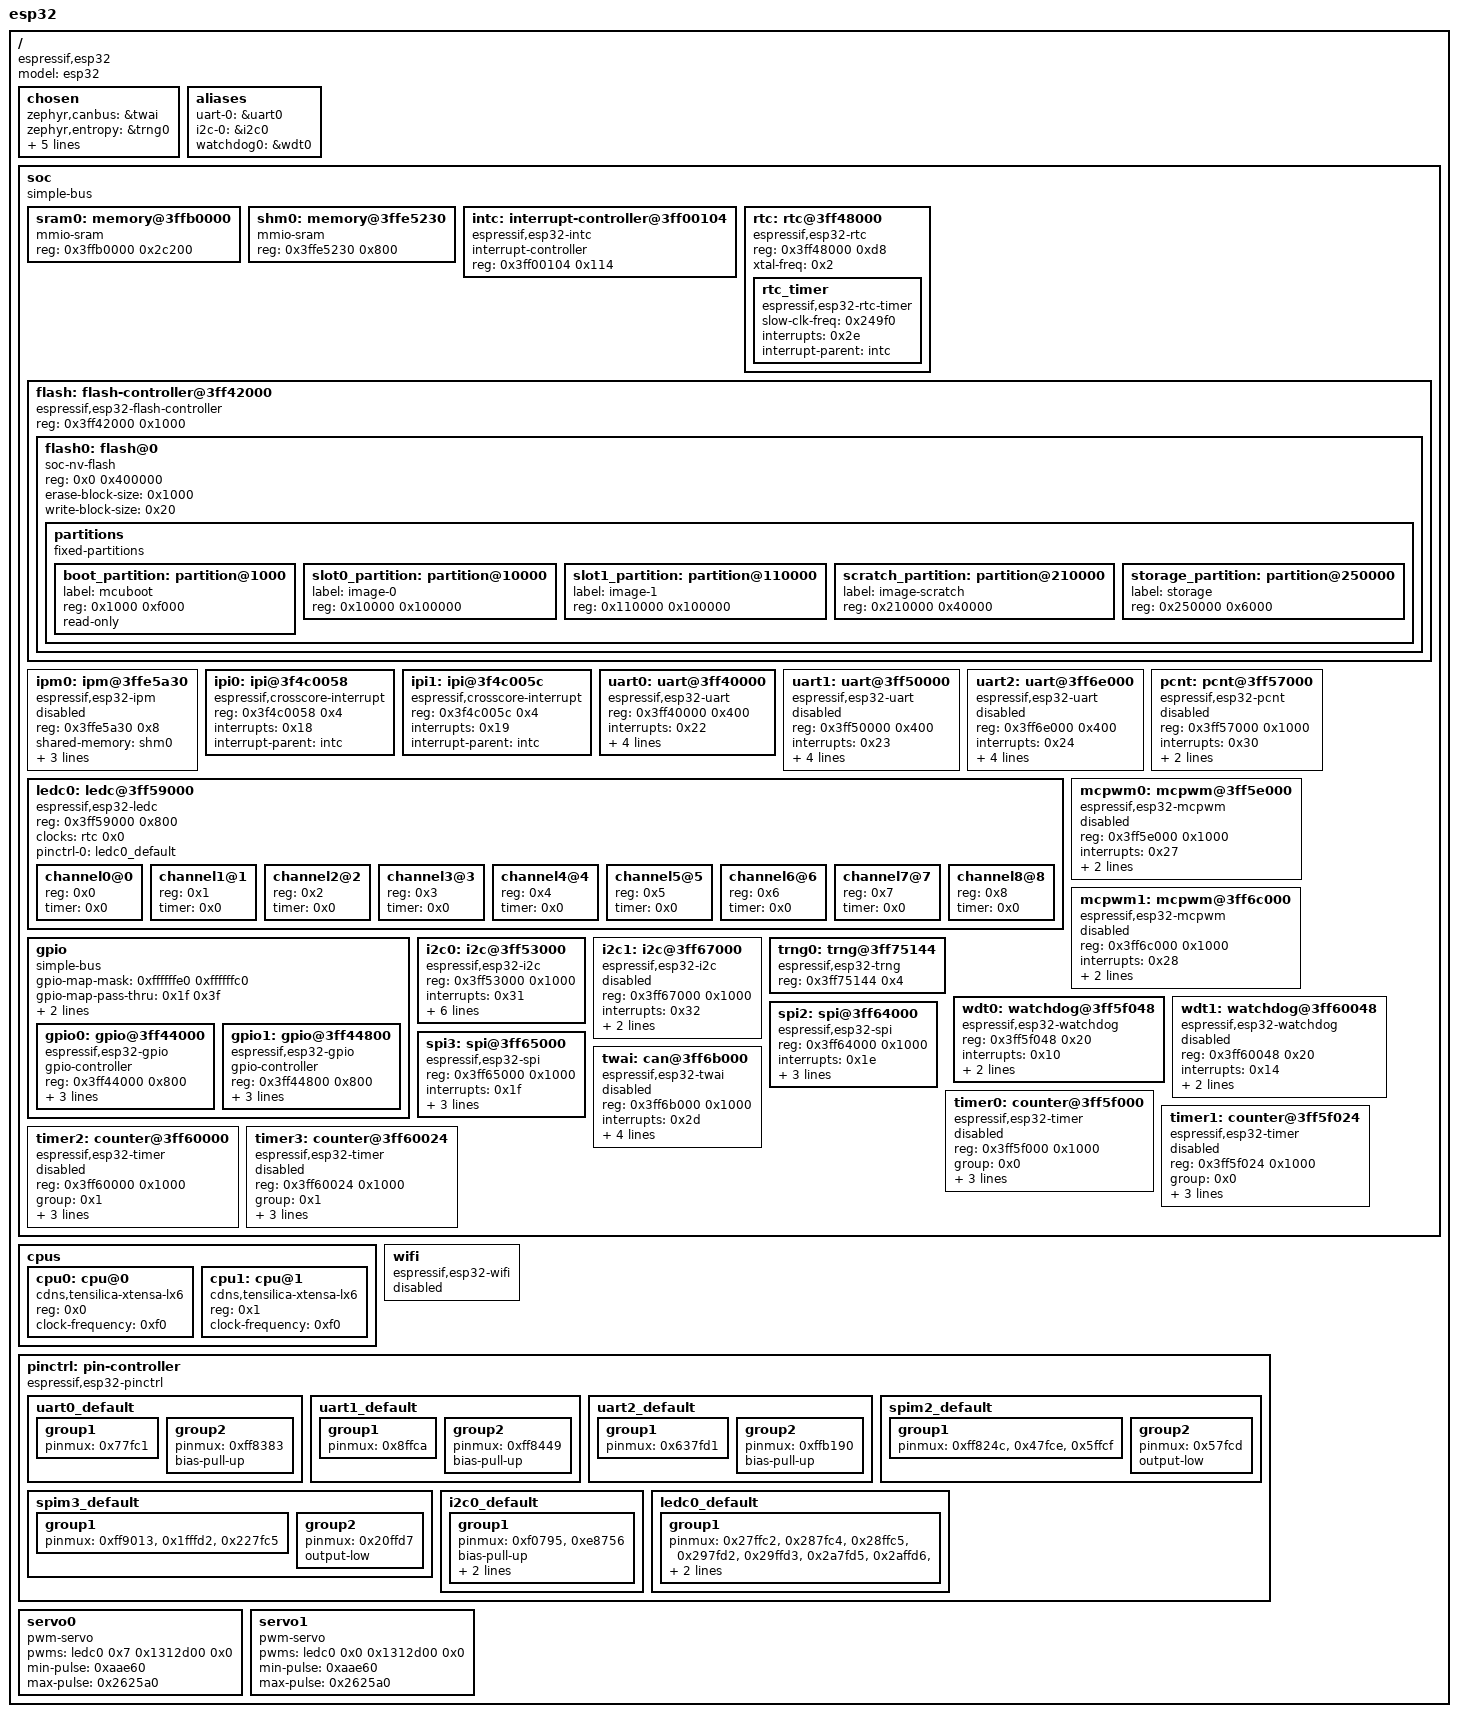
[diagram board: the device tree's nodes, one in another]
/dts-v1/;

/ {
	#address-cells = < 0x1 >;
	#size-cells = < 0x1 >;
	model = "esp32";
	compatible = "espressif,esp32";
	chosen {
		zephyr,canbus = &twai;
		zephyr,entropy = &trng0;
		zephyr,flash-controller = &flash;
		zephyr,sram = &sram0;
		zephyr,console = &uart0;
		zephyr,shell-uart = &uart0;
		zephyr,flash = &flash0;
	};
	aliases {
		uart-0 = &uart0;
		i2c-0 = &i2c0;
		watchdog0 = &wdt0;
	};
	soc {
		#address-cells = < 0x1 >;
		#size-cells = < 0x1 >;
		compatible = "simple-bus";
		ranges;
		sram0: memory@3ffb0000 {
			compatible = "mmio-sram";
			reg = < 0x3ffb0000 0x2c200 >;
		};
		shm0: memory@3ffe5230 {
			compatible = "mmio-sram";
			reg = < 0x3ffe5230 0x800 >;
			phandle = < 0x2 >;
		};
		intc: interrupt-controller@3ff00104 {
			#interrupt-cells = < 0x1 >;
			compatible = "espressif,esp32-intc";
			interrupt-controller;
			reg = < 0x3ff00104 0x114 >;
			status = "okay";
			phandle = < 0x1 >;
		};
		rtc: rtc@3ff48000 {
			compatible = "espressif,esp32-rtc";
			reg = < 0x3ff48000 0xd8 >;
			xtal-freq = < 0x2 >;
			#clock-cells = < 0x1 >;
			status = "okay";
			phandle = < 0x3 >;
			rtc_timer: rtc_timer {
				compatible = "espressif,esp32-rtc-timer";
				slow-clk-freq = < 0x249f0 >;
				interrupts = < 0x2e >;
				interrupt-parent = < &intc >;
				status = "okay";
			};
		};
		flash: flash-controller@3ff42000 {
			compatible = "espressif,esp32-flash-controller";
			reg = < 0x3ff42000 0x1000 >;
			#address-cells = < 0x1 >;
			#size-cells = < 0x1 >;
			flash0: flash@0 {
				compatible = "soc-nv-flash";
				reg = < 0x0 0x400000 >;
				erase-block-size = < 0x1000 >;
				write-block-size = < 0x20 >;
				status = "okay";
				partitions {
					compatible = "fixed-partitions";
					#address-cells = < 0x1 >;
					#size-cells = < 0x1 >;
					boot_partition: partition@1000 {
						label = "mcuboot";
						reg = < 0x1000 0xf000 >;
						read-only;
					};
					slot0_partition: partition@10000 {
						label = "image-0";
						reg = < 0x10000 0x100000 >;
					};
					slot1_partition: partition@110000 {
						label = "image-1";
						reg = < 0x110000 0x100000 >;
					};
					scratch_partition: partition@210000 {
						label = "image-scratch";
						reg = < 0x210000 0x40000 >;
					};
					storage_partition: partition@250000 {
						label = "storage";
						reg = < 0x250000 0x6000 >;
					};
				};
			};
		};
		ipm0: ipm@3ffe5a30 {
			compatible = "espressif,esp32-ipm";
			reg = < 0x3ffe5a30 0x8 >;
			status = "disabled";
			shared-memory = < &shm0 >;
			shared-memory-size = < 0x800 >;
			interrupts = < 0x18 0x19 >;
			interrupt-parent = < &intc >;
		};
		ipi0: ipi@3f4c0058 {
			compatible = "espressif,crosscore-interrupt";
			reg = < 0x3f4c0058 0x4 >;
			interrupts = < 0x18 >;
			interrupt-parent = < &intc >;
		};
		ipi1: ipi@3f4c005c {
			compatible = "espressif,crosscore-interrupt";
			reg = < 0x3f4c005c 0x4 >;
			interrupts = < 0x19 >;
			interrupt-parent = < &intc >;
		};
		uart0: uart@3ff40000 {
			compatible = "espressif,esp32-uart";
			reg = < 0x3ff40000 0x400 >;
			interrupts = < 0x22 >;
			interrupt-parent = < &intc >;
			clocks = < &rtc 0x1 >;
			status = "okay";
			current-speed = < 0x1c200 >;
			pinctrl-0 = < &uart0_default >;
			pinctrl-names = "default";
		};
		uart1: uart@3ff50000 {
			compatible = "espressif,esp32-uart";
			reg = < 0x3ff50000 0x400 >;
			interrupts = < 0x23 >;
			interrupt-parent = < &intc >;
			clocks = < &rtc 0x2 >;
			status = "disabled";
			current-speed = < 0x1c200 >;
			pinctrl-0 = < &uart1_default >;
			pinctrl-names = "default";
		};
		uart2: uart@3ff6e000 {
			compatible = "espressif,esp32-uart";
			reg = < 0x3ff6e000 0x400 >;
			interrupts = < 0x24 >;
			interrupt-parent = < &intc >;
			clocks = < &rtc 0x3 >;
			status = "disabled";
			current-speed = < 0x1c200 >;
			pinctrl-0 = < &uart2_default >;
			pinctrl-names = "default";
		};
		pcnt: pcnt@3ff57000 {
			compatible = "espressif,esp32-pcnt";
			reg = < 0x3ff57000 0x1000 >;
			interrupts = < 0x30 >;
			interrupt-parent = < &intc >;
			clocks = < &rtc 0x11 >;
			status = "disabled";
		};
		ledc0: ledc@3ff59000 {
			compatible = "espressif,esp32-ledc";
			#pwm-cells = < 0x3 >;
			reg = < 0x3ff59000 0x800 >;
			clocks = < &rtc 0x0 >;
			status = "okay";
			pinctrl-0 = < &ledc0_default >;
			pinctrl-names = "default";
			#address-cells = < 0x1 >;
			#size-cells = < 0x0 >;
			phandle = < 0xd >;
			channel0@0 {
				reg = < 0x0 >;
				timer = < 0x0 >;
			};
			channel1@1 {
				reg = < 0x1 >;
				timer = < 0x0 >;
			};
			channel2@2 {
				reg = < 0x2 >;
				timer = < 0x0 >;
			};
			channel3@3 {
				reg = < 0x3 >;
				timer = < 0x0 >;
			};
			channel4@4 {
				reg = < 0x4 >;
				timer = < 0x0 >;
			};
			channel5@5 {
				reg = < 0x5 >;
				timer = < 0x0 >;
			};
			channel6@6 {
				reg = < 0x6 >;
				timer = < 0x0 >;
			};
			channel7@7 {
				reg = < 0x7 >;
				timer = < 0x0 >;
			};
			channel8@8 {
				reg = < 0x8 >;
				timer = < 0x0 >;
			};
		};
		mcpwm0: mcpwm@3ff5e000 {
			compatible = "espressif,esp32-mcpwm";
			reg = < 0x3ff5e000 0x1000 >;
			interrupts = < 0x27 >;
			interrupt-parent = < &intc >;
			clocks = < &rtc 0xa >;
			#pwm-cells = < 0x3 >;
			status = "disabled";
		};
		mcpwm1: mcpwm@3ff6c000 {
			compatible = "espressif,esp32-mcpwm";
			reg = < 0x3ff6c000 0x1000 >;
			interrupts = < 0x28 >;
			interrupt-parent = < &intc >;
			clocks = < &rtc 0xb >;
			#pwm-cells = < 0x3 >;
			status = "disabled";
		};
		gpio: gpio {
			compatible = "simple-bus";
			gpio-map-mask = < 0xffffffe0 0xffffffc0 >;
			gpio-map-pass-thru = < 0x1f 0x3f >;
			gpio-map = < 0x0 0x0 &gpio0 0x0 0x0 0x20 0x0 &gpio1 0x0 0x0 >;
			#gpio-cells = < 0x2 >;
			#address-cells = < 0x1 >;
			#size-cells = < 0x1 >;
			ranges;
			gpio0: gpio@3ff44000 {
				compatible = "espressif,esp32-gpio";
				gpio-controller;
				#gpio-cells = < 0x2 >;
				reg = < 0x3ff44000 0x800 >;
				interrupts = < 0x16 >;
				interrupt-parent = < &intc >;
				ngpios = < 0x20 >;
				status = "okay";
				phandle = < 0x8 >;
			};
			gpio1: gpio@3ff44800 {
				compatible = "espressif,esp32-gpio";
				gpio-controller;
				#gpio-cells = < 0x2 >;
				reg = < 0x3ff44800 0x800 >;
				interrupts = < 0x16 >;
				interrupt-parent = < &intc >;
				ngpios = < 0x8 >;
				status = "okay";
				phandle = < 0x9 >;
			};
		};
		i2c0: i2c@3ff53000 {
			compatible = "espressif,esp32-i2c";
			#address-cells = < 0x1 >;
			#size-cells = < 0x0 >;
			reg = < 0x3ff53000 0x1000 >;
			interrupts = < 0x31 >;
			interrupt-parent = < &intc >;
			clocks = < &rtc 0x4 >;
			status = "okay";
			clock-frequency = < 0x186a0 >;
			sda-gpios = < &gpio0 0x15 0x6 >;
			scl-gpios = < &gpio0 0x16 0x6 >;
			pinctrl-0 = < &i2c0_default >;
			pinctrl-names = "default";
		};
		i2c1: i2c@3ff67000 {
			compatible = "espressif,esp32-i2c";
			#address-cells = < 0x1 >;
			#size-cells = < 0x0 >;
			reg = < 0x3ff67000 0x1000 >;
			interrupts = < 0x32 >;
			interrupt-parent = < &intc >;
			clocks = < &rtc 0x5 >;
			status = "disabled";
		};
		trng0: trng@3ff75144 {
			compatible = "espressif,esp32-trng";
			reg = < 0x3ff75144 0x4 >;
			status = "okay";
		};
		wdt0: watchdog@3ff5f048 {
			compatible = "espressif,esp32-watchdog";
			reg = < 0x3ff5f048 0x20 >;
			interrupts = < 0x10 >;
			interrupt-parent = < &intc >;
			clocks = < &rtc 0x8 >;
			status = "okay";
		};
		wdt1: watchdog@3ff60048 {
			compatible = "espressif,esp32-watchdog";
			reg = < 0x3ff60048 0x20 >;
			interrupts = < 0x14 >;
			interrupt-parent = < &intc >;
			clocks = < &rtc 0x9 >;
			status = "disabled";
		};
		spi2: spi@3ff64000 {
			compatible = "espressif,esp32-spi";
			reg = < 0x3ff64000 0x1000 >;
			interrupts = < 0x1e >;
			interrupt-parent = < &intc >;
			clocks = < &rtc 0x13 >;
			status = "okay";
			#address-cells = < 0x1 >;
			#size-cells = < 0x0 >;
			pinctrl-0 = < &spim2_default >;
			pinctrl-names = "default";
		};
		spi3: spi@3ff65000 {
			compatible = "espressif,esp32-spi";
			reg = < 0x3ff65000 0x1000 >;
			interrupts = < 0x1f >;
			interrupt-parent = < &intc >;
			clocks = < &rtc 0x14 >;
			status = "okay";
			#address-cells = < 0x1 >;
			#size-cells = < 0x0 >;
			pinctrl-0 = < &spim3_default >;
			pinctrl-names = "default";
		};
		twai: can@3ff6b000 {
			compatible = "espressif,esp32-twai";
			reg = < 0x3ff6b000 0x1000 >;
			interrupts = < 0x2d >;
			interrupt-parent = < &intc >;
			clocks = < &rtc 0x18 >;
			sjw = < 0x1 >;
			sample-point = < 0x36b >;
			status = "disabled";
		};
		timer0: counter@3ff5f000 {
			compatible = "espressif,esp32-timer";
			reg = < 0x3ff5f000 0x1000 >;
			group = < 0x0 >;
			index = < 0x0 >;
			interrupts = < 0xe >;
			interrupt-parent = < &intc >;
			status = "disabled";
		};
		timer1: counter@3ff5f024 {
			compatible = "espressif,esp32-timer";
			reg = < 0x3ff5f024 0x1000 >;
			group = < 0x0 >;
			index = < 0x1 >;
			interrupts = < 0xf >;
			interrupt-parent = < &intc >;
			status = "disabled";
		};
		timer2: counter@3ff60000 {
			compatible = "espressif,esp32-timer";
			reg = < 0x3ff60000 0x1000 >;
			group = < 0x1 >;
			index = < 0x0 >;
			interrupts = < 0x12 >;
			interrupt-parent = < &intc >;
			status = "disabled";
		};
		timer3: counter@3ff60024 {
			compatible = "espressif,esp32-timer";
			reg = < 0x3ff60024 0x1000 >;
			group = < 0x1 >;
			index = < 0x1 >;
			interrupts = < 0x13 >;
			interrupt-parent = < &intc >;
			status = "disabled";
		};
	};
	cpus {
		#address-cells = < 0x1 >;
		#size-cells = < 0x0 >;
		cpu0: cpu@0 {
			device_type = "cpu";
			compatible = "cdns,tensilica-xtensa-lx6";
			reg = < 0x0 >;
			clock-frequency = < 0xf0 >;
		};
		cpu1: cpu@1 {
			device_type = "cpu";
			compatible = "cdns,tensilica-xtensa-lx6";
			reg = < 0x1 >;
			clock-frequency = < 0xf0 >;
		};
	};
	wifi: wifi {
		compatible = "espressif,esp32-wifi";
		status = "disabled";
	};
	pinctrl: pin-controller {
		compatible = "espressif,esp32-pinctrl";
		status = "okay";
		uart0_default: uart0_default {
			phandle = < 0x4 >;
			group1 {
				pinmux = < 0x77fc1 >;
			};
			group2 {
				pinmux = < 0xff8383 >;
				bias-pull-up;
			};
		};
		uart1_default: uart1_default {
			phandle = < 0x5 >;
			group1 {
				pinmux = < 0x8ffca >;
			};
			group2 {
				pinmux = < 0xff8449 >;
				bias-pull-up;
			};
		};
		uart2_default: uart2_default {
			phandle = < 0x6 >;
			group1 {
				pinmux = < 0x637fd1 >;
			};
			group2 {
				pinmux = < 0xffb190 >;
				bias-pull-up;
			};
		};
		spim2_default: spim2_default {
			phandle = < 0xb >;
			group1 {
				pinmux = < 0xff824c >, < 0x47fce >, < 0x5ffcf >;
			};
			group2 {
				pinmux = < 0x57fcd >;
				output-low;
			};
		};
		spim3_default: spim3_default {
			phandle = < 0xc >;
			group1 {
				pinmux = < 0xff9013 >, < 0x1fffd2 >, < 0x227fc5 >;
			};
			group2 {
				pinmux = < 0x20ffd7 >;
				output-low;
			};
		};
		i2c0_default: i2c0_default {
			phandle = < 0xa >;
			group1 {
				pinmux = < 0xf0795 >, < 0xe8756 >;
				bias-pull-up;
				drive-open-drain;
				output-high;
			};
		};
		ledc0_default: ledc0_default {
			phandle = < 0x7 >;
			group1 {
				pinmux = < 0x27ffc2 >, < 0x287fc4 >, < 0x28ffc5 >, < 0x297fd2 >, < 0x29ffd3 >, < 0x2a7fd5 >, < 0x2affd6 >, < 0x2b7fd7 >, < 0x23ffcf >;
				output-enable;
			};
		};
	};
	servo0: servo0 {
		compatible = "pwm-servo";
		pwms = < &ledc0 0x7 0x1312d00 0x0 >;
		min-pulse = < 0xaae60 >;
		max-pulse = < 0x2625a0 >;
	};
	servo1: servo1 {
		compatible = "pwm-servo";
		pwms = < &ledc0 0x0 0x1312d00 0x0 >;
		min-pulse = < 0xaae60 >;
		max-pulse = < 0x2625a0 >;
	};
};
